# ATSAMA5D27 register map
Vendor: Microchip Technology Inc.; File version: 1.0
CPU: CA5 r0p1, little endian, no MPU, no FPU, 4 interrupt priority bits
Address unit: 32 bits
Registers are 32-bit, read-write, reset 0x0 unless marked. A register's access mark holds for its fields unless they carry their own. Offsets are from the block's base; [hi:lo] are bit positions.

## UART0 — Universal Asynchronous Receiver Transmitter
Base 0xF801C000
Same registers: UART1 0xF8020000, UART2 0xF8024000, UART3 0xFC008000, UART4 0xFC00C000
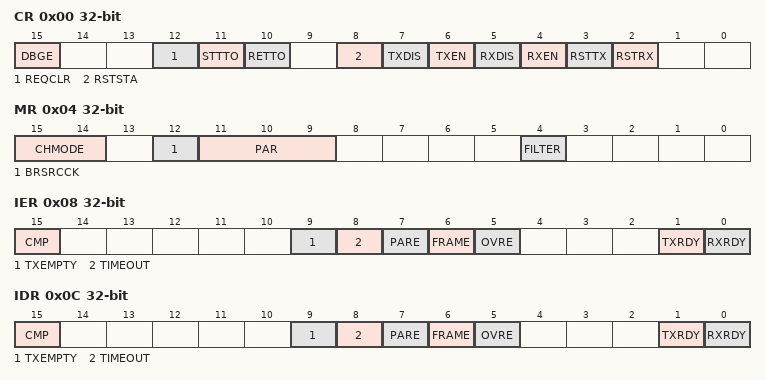
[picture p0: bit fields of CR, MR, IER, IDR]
0x00 CR wo — Control Register
  [15] DBGE rw — Debug Enable
  [12] REQCLR rw — Request Clear
  [11] STTTO rw — Start Time-out
  [10] RETTO rw — Rearm Time-out
  [8] RSTSTA rw — Reset Status
  [7] TXDIS rw — Transmitter Disable
  [6] TXEN rw — Transmitter Enable
  [5] RXDIS rw — Receiver Disable
  [4] RXEN rw — Receiver Enable
  [3] RSTTX rw — Reset Transmitter
  [2] RSTRX rw — Reset Receiver
0x04 MR — Mode Register
  [15:14] CHMODE — Channel Mode
    0=NORMAL (Normal mode); 1=AUTOMATIC (Automatic echo); 2=LOCAL_LOOPBACK; 3=REMOTE_LOOPBACK
  [12] BRSRCCK — Baud Rate Source Clock
    0=PERIPH_CLK (The baud rate is driven by the peripheral clock); 1=GCLK (The baud rate is driven by a PMC-programmable clock GCLK (see section Power Management Controller (PMC)).)
  [11:9] PAR — Parity Type
    0=EVEN (Even Parity); 1=ODD (Odd Parity); 2=SPACE (Space: parity forced to 0); 3=MARK (Mark: parity forced to 1); 4=NO (No parity)
  [4] FILTER — Receiver Digital Filter
    0=DISABLED (UART does not filter the receive line.); 1=ENABLED (UART filters the receive line using a three-sample filter (16x-bit clock) (2 over 3 majority).)
0x08 IER wo — Interrupt Enable Register
  [15] CMP rw — Enable Comparison Interrupt
  [9] TXEMPTY rw — Enable TXEMPTY Interrupt
  [8] TIMEOUT rw — Enable Time-out Interrupt
  [7] PARE rw — Enable Parity Error Interrupt
  [6] FRAME rw — Enable Framing Error Interrupt
  [5] OVRE rw — Enable Overrun Error Interrupt
  [1] TXRDY rw — Enable TXRDY Interrupt
  [0] RXRDY rw — Enable RXRDY Interrupt
0x0C IDR wo — Interrupt Disable Register
  [15] CMP rw — Disable Comparison Interrupt
  [9] TXEMPTY rw — Disable TXEMPTY Interrupt
  [8] TIMEOUT rw — Disable Time-out Interrupt
  [7] PARE rw — Disable Parity Error Interrupt
  [6] FRAME rw — Disable Framing Error Interrupt
  [5] OVRE rw — Disable Overrun Error Interrupt
  [1] TXRDY rw — Disable TXRDY Interrupt
  [0] RXRDY rw — Disable RXRDY Interrupt
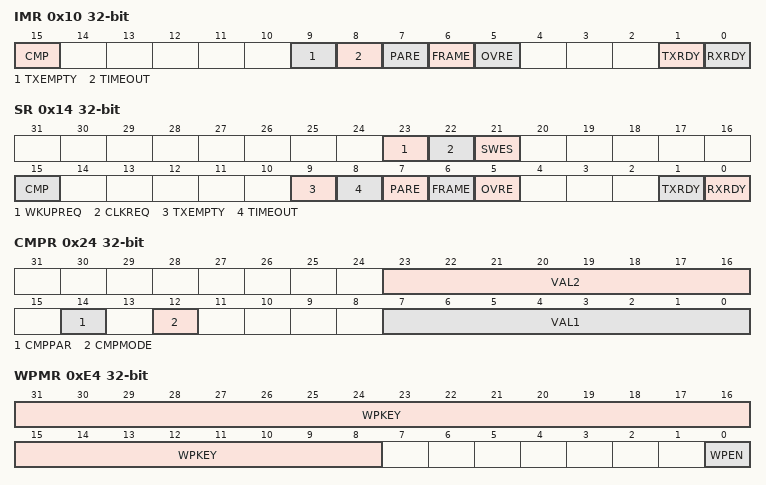
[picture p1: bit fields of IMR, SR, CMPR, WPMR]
0x10 IMR ro — Interrupt Mask Register
  [15] CMP rw — Mask Comparison Interrupt
  [9] TXEMPTY rw — Mask TXEMPTY Interrupt
  [8] TIMEOUT rw — Mask Time-out Interrupt
  [7] PARE rw — Mask Parity Error Interrupt
  [6] FRAME rw — Mask Framing Error Interrupt
  [5] OVRE rw — Mask Overrun Error Interrupt
  [1] TXRDY rw — Disable TXRDY Interrupt
  [0] RXRDY rw — Mask RXRDY Interrupt
0x14 SR ro — Status Register
  [23] WKUPREQ rw — Wake-Up Request
  [22] CLKREQ rw — Clock Request
  [21] SWES rw — SleepWalking Enable Status
  [15] CMP rw — Comparison Match
  [9] TXEMPTY rw — Transmitter Empty
  [8] TIMEOUT rw — Receiver Time-out
  [7] PARE rw — Parity Error
  [6] FRAME rw — Framing Error
  [5] OVRE rw — Overrun Error
  [1] TXRDY rw — Transmitter Ready
  [0] RXRDY rw — Receiver Ready
0x18 RHR ro — Receive Holding Register
  [7:0] RXCHR rw — Received Character
0x1C THR wo — Transmit Holding Register
  [7:0] TXCHR rw — Character to be Transmitted
0x20 BRGR — Baud Rate Generator Register
  [15:0] CD — Clock Divisor
0x24 CMPR — Comparison Register
  [23:16] VAL2 — Second Comparison Value for Received Character
  [14] CMPPAR — Compare Parity
  [12] CMPMODE — Comparison Mode
    0=FLAG_ONLY (Any character is received and comparison function drives CMP flag.); 1=START_CONDITION (Comparison condition must be met to start reception.)
  [7:0] VAL1 — First Comparison Value for Received Character
0x28 RTOR — Receiver Time-out Register
  [7:0] TO — Time-out Value
0xE4 WPMR — Write Protection Mode Register
  [31:8] WPKEY — Write Protection Key
    0x554152=PASSWD (Writing any other value in this field aborts the write operation.Always reads as 0.)
  [0] WPEN — Write Protection Enable
